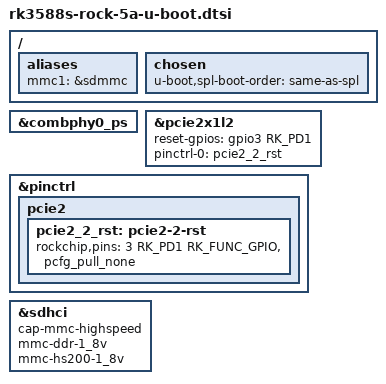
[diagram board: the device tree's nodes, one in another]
// SPDX-License-Identifier: (GPL-2.0+ OR MIT)
/*
 * Copyright (c) 2023 Collabora Ltd.
 */

#include "rk3588s-u-boot.dtsi"

/ {
	aliases {
		mmc1 = &sdmmc;
	};

	chosen {
		u-boot,spl-boot-order = "same-as-spl", &sdmmc, &sdhci;
	};
};

&combphy0_ps {
	status = "okay";
};

&pcie2x1l2 {
	reset-gpios = <&gpio3 RK_PD1 GPIO_ACTIVE_HIGH>;
	pinctrl-0 = <&pcie2_2_rst>;
	status = "okay";
};

&pinctrl {
	pcie2 {
		pcie2_2_rst: pcie2-2-rst {
			rockchip,pins = <3 RK_PD1 RK_FUNC_GPIO &pcfg_pull_none>;
		};
	};
};

&sdhci {
	cap-mmc-highspeed;
	mmc-ddr-1_8v;
	mmc-hs200-1_8v;
};
